# STM32H725ZGT7 register map
File version: 1.0
Registers are 32-bit, access not given, reset 0x0 unless marked. A register's access mark holds for its fields unless they carry their own. Offsets are from the block's base; [hi:lo] are bit positions; {n}, {i} and the like mark numbered series; 'fields as' and 'values as' point back to an identical list.

## COMP12
Base 0x58003800
0x00 SR
0x04 ICFR
0x08 OR

## COMP1
Base 0x5800380C
Same registers: COMP2 0x58003810, COMP12_COMMON 0x58003810
0x00 CFGR

## VREFBUF
Base 0x58003C00
0x00 CSR
  [5] VRS_OUT3, [5:4] VRS_OUT4, [3] VRR, [1] HIZ, [0] ENVR
0x04 CCR
  [5:0] TRIM

## RTC
Base 0x58004000
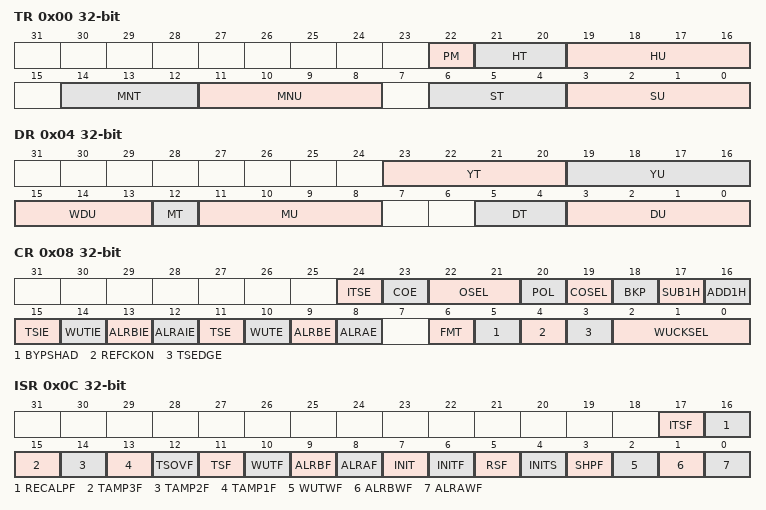
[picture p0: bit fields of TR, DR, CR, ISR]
0x00 TR
  [22] PM, [21:20] HT, [19:16] HU, [14:12] MNT, [11:8] MNU, [6:4] ST, [3:0] SU
0x04 DR
  [23:20] YT, [19:16] YU, [15:13] WDU, [12] MT, [11:8] MU, [5:4] DT, [3:0] DU
0x08 CR
  [24] ITSE, [23] COE, [22:21] OSEL, [20] POL, [19] COSEL, [18] BKP, [17] SUB1H, [16] ADD1H, [15] TSIE, [14] WUTIE, [13] ALRBIE, [12] ALRAIE, [11] TSE, [10] WUTE, [9] ALRBE, [8] ALRAE, [6] FMT, [5] BYPSHAD, [4] REFCKON, [3] TSEDGE, [2:0] WUCKSEL
0x0C ISR
  [17] ITSF, [16] RECALPF, [15] TAMP3F, [14] TAMP2F, [13] TAMP1F, [12] TSOVF, [11] TSF, [10] WUTF, [9] ALRBF, [8] ALRAF, [7] INIT, [6] INITF, [5] RSF, [4] INITS, [3] SHPF, [2] WUTWF, [1] ALRBWF, [0] ALRAWF
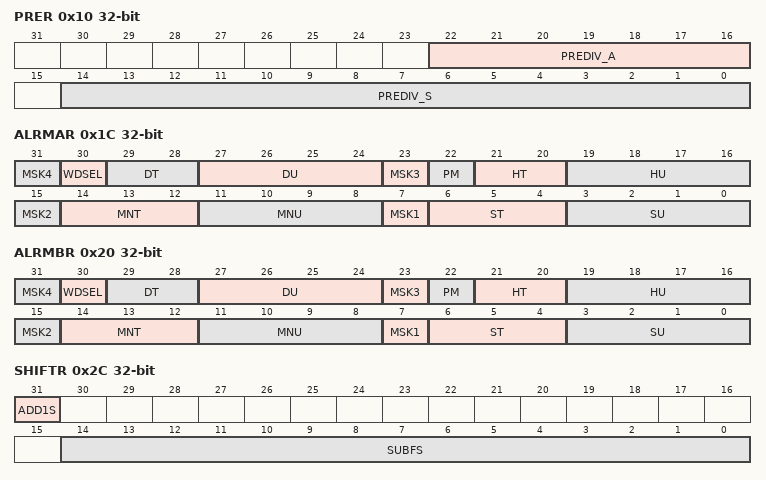
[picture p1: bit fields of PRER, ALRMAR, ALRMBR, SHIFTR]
0x10 PRER
  [22:16] PREDIV_A, [14:0] PREDIV_S
0x14 WUTR
  [15:0] WUT
0x1C ALRMAR
  [8n-1] MSK{n} (n=1..4), [30] WDSEL, [29:28] DT, [27:24] DU, [22] PM, [21:20] HT, [19:16] HU, [14:12] MNT, [11:8] MNU, [6:4] ST, [3:0] SU
0x20 ALRMBR
  fields as ALRMAR
0x24 WPR
  [7:0] KEY
0x28 SSR
  [15:0] SS
0x2C SHIFTR
  [31] ADD1S, [14:0] SUBFS
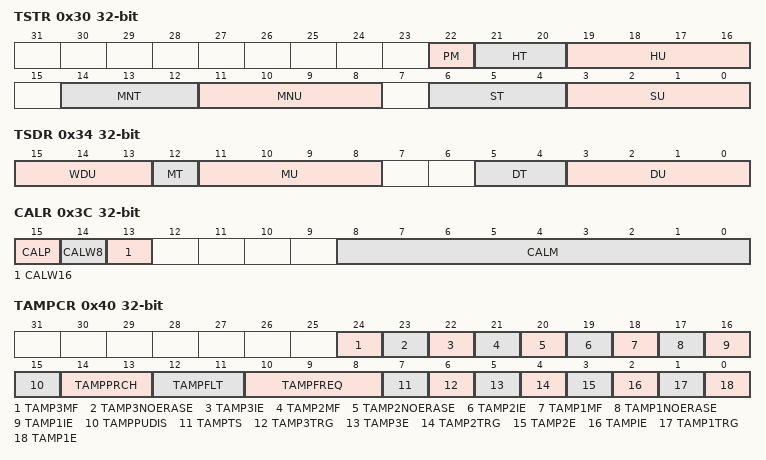
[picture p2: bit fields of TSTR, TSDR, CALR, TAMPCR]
0x30 TSTR
  fields as TR
0x34 TSDR
  [15:13] WDU, [12] MT, [11:8] MU, [5:4] DT, [3:0] DU
0x38 TSSSR
  [15:0] SS
0x3C CALR
  [15] CALP, [14] CALW8, [13] CALW16, [8:0] CALM
0x40 TAMPCR
  [24] TAMP3MF, [23] TAMP3NOERASE, [22] TAMP3IE, [21] TAMP2MF, [20] TAMP2NOERASE, [19] TAMP2IE, [18] TAMP1MF, [17] TAMP1NOERASE, [16] TAMP1IE, [15] TAMPPUDIS, [14:13] TAMPPRCH, [12:11] TAMPFLT, [10:8] TAMPFREQ, [7] TAMPTS, [6] TAMP3TRG, [5] TAMP3E, [4] TAMP2TRG, [3] TAMP2E, [2] TAMPIE, [1] TAMP1TRG, [0] TAMP1E
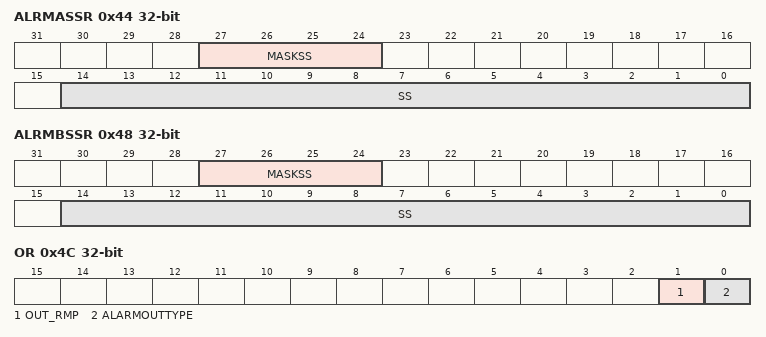
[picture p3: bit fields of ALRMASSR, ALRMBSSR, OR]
0x44 ALRMASSR
  [27:24] MASKSS, [14:0] SS
0x48 ALRMBSSR
  [27:24] MASKSS, [14:0] SS
0x4C OR
  [1] OUT_RMP, [0] ALARMOUTTYPE
{0x50+4i} BKP{i}R (i=0..31)

## IWDG1
Base 0x58004800
0x00 KR
  [15:0] KEY
0x04 PR
  [2:0] PR
0x08 RLR
  [11:0] RL
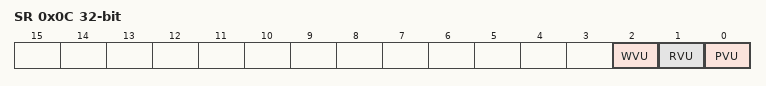
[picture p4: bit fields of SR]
0x0C SR
  [2] WVU, [1] RVU, [0] PVU
0x10 WINR
  [11:0] WIN

## DTS
Base 0x58006800
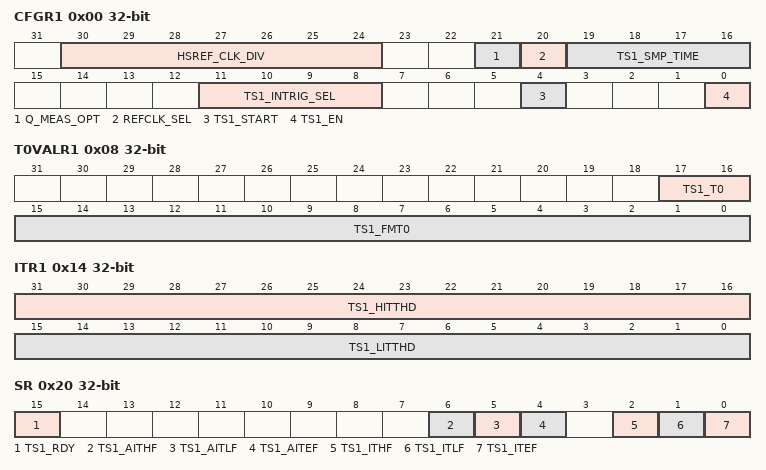
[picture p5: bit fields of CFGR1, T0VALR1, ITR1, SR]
0x00 CFGR1
  [30:24] HSREF_CLK_DIV, [21] Q_MEAS_OPT, [20] REFCLK_SEL, [19:16] TS1_SMP_TIME, [11:8] TS1_INTRIG_SEL, [4] TS1_START, [0] TS1_EN
0x08 T0VALR1
  [17:16] TS1_T0, [15:0] TS1_FMT0
0x10 RAMPVALR
  [15:0] TS1_RAMP_COEFF
0x14 ITR1
  [31:16] TS1_HITTHD, [15:0] TS1_LITTHD
0x1C DR
  [15:0] TS1_MFREQ
0x20 SR
  [15] TS1_RDY, [6] TS1_AITHF, [5] TS1_AITLF, [4] TS1_AITEF, [2] TS1_ITHF, [1] TS1_ITLF, [0] TS1_ITEF
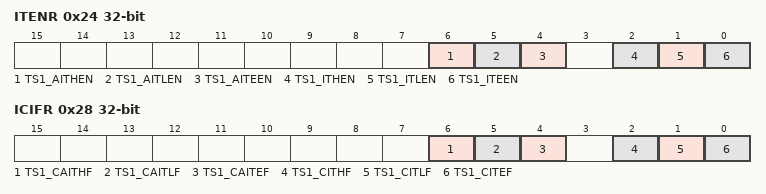
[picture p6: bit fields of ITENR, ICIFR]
0x24 ITENR
  [6] TS1_AITHEN, [5] TS1_AITLEN, [4] TS1_AITEEN, [2] TS1_ITHEN, [1] TS1_ITLEN, [0] TS1_ITEEN
0x28 ICIFR
  [6] TS1_CAITHF, [5] TS1_CAITLF, [4] TS1_CAITEF, [2] TS1_CITHF, [1] TS1_CITLF, [0] TS1_CITEF
0x2C OR

## GPIOA
Base 0x58020000
Same registers: GPIOB 0x58020400, GPIOC 0x58020800, GPIOD 0x58020C00, GPIOE 0x58021000, GPIOF 0x58021400, GPIOG 0x58021800, GPIOH 0x58021C00, GPIOJ 0x58022400, GPIOK 0x58022800
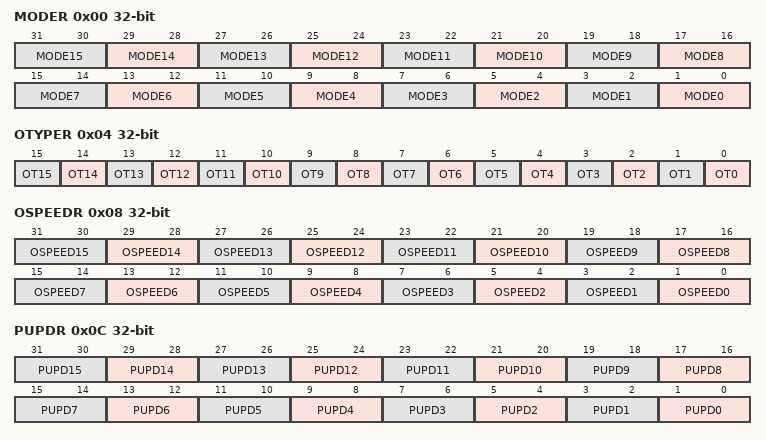
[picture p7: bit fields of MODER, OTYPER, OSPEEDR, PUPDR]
0x00 MODER
  [2n+1:2n] MODE{n} (n=0..15)
0x04 OTYPER
  [n] OT{n} (n=0..15)
0x08 OSPEEDR
  [2n+1:2n] OSPEED{n} (n=0..15)
0x0C PUPDR
  [2n+1:2n] PUPD{n} (n=0..15)
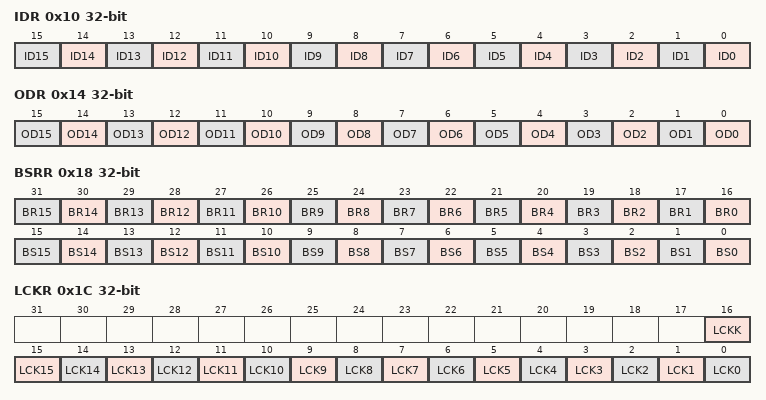
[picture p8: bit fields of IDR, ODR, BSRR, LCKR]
0x10 IDR
  [n] ID{n} (n=0..15)
0x14 ODR
  [n] OD{n} (n=0..15)
0x18 BSRR
  [n+16] BR{n} (n=0..15), [n] BS{n} (n=0..15)
0x1C LCKR
  [16] LCKK, [n] LCK{n} (n=0..15)
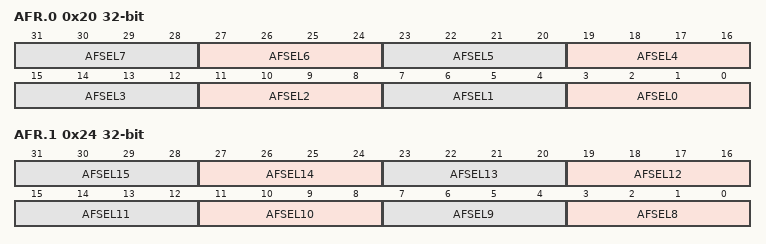
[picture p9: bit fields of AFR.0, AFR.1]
0x20 AFR.0
  [4n+3:4n] AFSEL{n} (n=0..7)
0x24 AFR.1
  [4n-29:4n-32] AFSEL{n} (n=8..15)

## PWR
Base 0x58024800
0x00 CR1
  [18] ALS_LEV2, [18:17] ALS_LEV3, [16] AVDEN, [15:14] SVOS, [9] FLPS, [8] DBP, [7] PLS_LEV4, [7:6] PLS_LEV6, [7:5] PLS_LEV7, [4] PVDEN, [0] LPDS
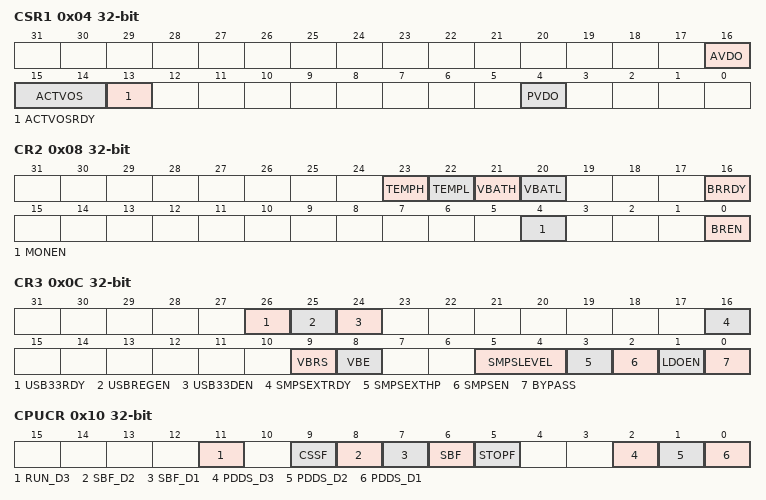
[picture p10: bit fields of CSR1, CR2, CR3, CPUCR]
0x04 CSR1
  [16] AVDO, [15:14] ACTVOS, [13] ACTVOSRDY, [4] PVDO
0x08 CR2
  [23] TEMPH, [22] TEMPL, [21] VBATH, [20] VBATL, [16] BRRDY, [4] MONEN, [0] BREN
0x0C CR3
  [26] USB33RDY, [25] USBREGEN, [24] USB33DEN, [16] SMPSEXTRDY, [9] VBRS, [8] VBE, [5:4] SMPSLEVEL, [3] SMPSEXTHP, [2] SMPSEN, [1] LDOEN, [0] BYPASS
0x10 CPUCR
  [11] RUN_D3, [9] CSSF, [8] SBF_D2, [7] SBF_D1, [6] SBF, [5] STOPF, [2] PDDS_D3, [1] PDDS_D2, [0] PDDS_D1
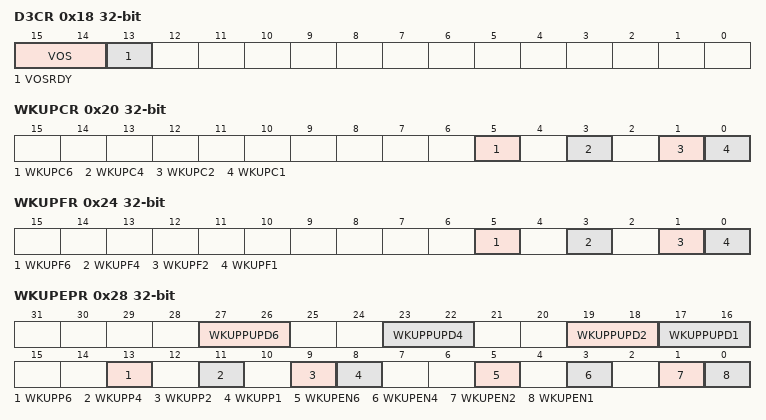
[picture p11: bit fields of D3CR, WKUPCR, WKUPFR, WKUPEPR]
0x18 D3CR
  [15:14] VOS, [13] VOSRDY
0x20 WKUPCR
  [5] WKUPC6, [3] WKUPC4, [1] WKUPC2, [0] WKUPC1
0x24 WKUPFR
  [5] WKUPF6, [3] WKUPF4, [1] WKUPF2, [0] WKUPF1
0x28 WKUPEPR
  [27:26] WKUPPUPD6, [23:22] WKUPPUPD4, [19:18] WKUPPUPD2, [17:16] WKUPPUPD1, [13] WKUPP6, [11] WKUPP4, [9] WKUPP2, [8] WKUPP1, [5] WKUPEN6, [3] WKUPEN4, [1] WKUPEN2, [0] WKUPEN1
